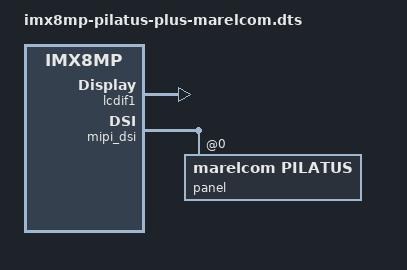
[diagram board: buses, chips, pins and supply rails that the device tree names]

/*
 * Copyright 2022 Bruetsch Elektronik AG
 */

#include "imx8mp-pilatus-plus.dts"

/* MIPI-DSI */
&lcdif1 {
	status = "okay";
};

&mipi_dsi {
	status = "okay";
	panel@0 {
	
		compatible = "marelcom,pilatus";
		reg = <0>;
		dsi-lanes = <4>;
		video-mode = <2>;	/* 0: burst mode
					 * 1: non-burst mode with sync event
					 * 2: non-burst mode with sync pulse
					 */
		status = "okay";
	};
};

/* LVDS */
&lcdif2 {
	status = "disabled";
};

&ldb {
	status = "disabled";
};

&ldb_phy {
	status = "disabled";
};


&iomuxc {
	pinctrl_captouch: captouchgrp {
		fsl,pins = <
			MX8MP_IOMUXC_SPDIF_TX__GPIO5_IO03 		0x16
		>;
	};
};
